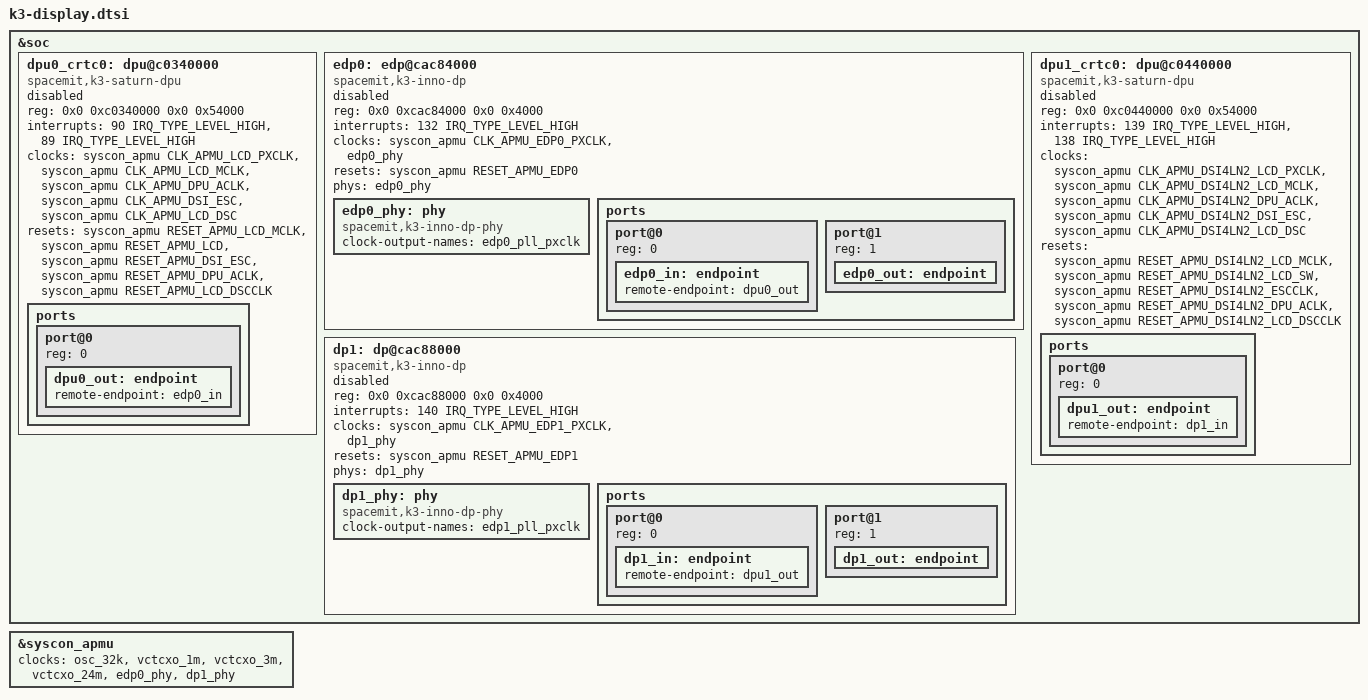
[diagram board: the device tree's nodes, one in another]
// SPDX-License-Identifier: (GPL-2.0 OR MIT)
/*
 * SpacemiT K3 display subsystem (DPU0/eDP0 + DPU1/DP1) shared
 * device-tree definitions for inclusion alongside k3.dtsi.
 *
 * Copyright (C) 2026 SpacemiT Co., Ltd.
 */

#include <dt-bindings/clock/spacemit,k3-clocks.h>
#include <dt-bindings/reset/spacemit,k3-resets.h>
#include <dt-bindings/interrupt-controller/irq.h>

&soc {
	dpu0_crtc0: dpu@c0340000 {
		compatible = "spacemit,k3-saturn-dpu";
		reg = <0x0 0xc0340000 0x0 0x54000>;
		interrupts = <90 IRQ_TYPE_LEVEL_HIGH>,
			     <89 IRQ_TYPE_LEVEL_HIGH>;
		interrupt-names = "online", "offline";
		clocks = <&syscon_apmu CLK_APMU_LCD_PXCLK>,
			 <&syscon_apmu CLK_APMU_LCD_MCLK>,
			 <&syscon_apmu CLK_APMU_DPU_ACLK>,
			 <&syscon_apmu CLK_APMU_DSI_ESC>,
			 <&syscon_apmu CLK_APMU_LCD_DSC>;
		clock-names = "pxclk", "mclk", "aclk", "escclk", "dscclk";
		resets = <&syscon_apmu RESET_APMU_LCD_MCLK>,
			 <&syscon_apmu RESET_APMU_LCD>,
			 <&syscon_apmu RESET_APMU_DSI_ESC>,
			 <&syscon_apmu RESET_APMU_DPU_ACLK>,
			 <&syscon_apmu RESET_APMU_LCD_DSCCLK>;
		reset-names = "mclk", "lcd", "esc",
			      "aclk", "dsc";
		status = "disabled";

		ports {
			#address-cells = <1>;
			#size-cells = <0>;

			port@0 {
				reg = <0>;
				dpu0_out: endpoint {
					remote-endpoint = <&edp0_in>;
				};
			};
		};
	};

	edp0: edp@cac84000 {
		compatible = "spacemit,k3-inno-dp";
		reg = <0x0 0xcac84000 0x0 0x4000>;
		interrupts = <132 IRQ_TYPE_LEVEL_HIGH>;
		clocks = <&syscon_apmu CLK_APMU_EDP0_PXCLK>, <&edp0_phy>;
		clock-names = "pxclk", "pll";
		resets = <&syscon_apmu RESET_APMU_EDP0>;
		phys = <&edp0_phy>;
		phy-names = "dp";
		status = "disabled";

		edp0_phy: phy {
			compatible = "spacemit,k3-inno-dp-phy";
			#phy-cells = <0>;
			#clock-cells = <0>;
			clock-output-names = "edp0_pll_pxclk";
		};

		ports {
			#address-cells = <1>;
			#size-cells = <0>;

			port@0 {
				reg = <0>;
				edp0_in: endpoint {
					remote-endpoint = <&dpu0_out>;
				};
			};

			port@1 {
				reg = <1>;
				edp0_out: endpoint {
				};
			};
		};
	};

	dpu1_crtc0: dpu@c0440000 {
		compatible = "spacemit,k3-saturn-dpu";
		reg = <0x0 0xc0440000 0x0 0x54000>;
		interrupts = <139 IRQ_TYPE_LEVEL_HIGH>,
			     <138 IRQ_TYPE_LEVEL_HIGH>;
		interrupt-names = "online", "offline";
		clocks = <&syscon_apmu CLK_APMU_DSI4LN2_LCD_PXCLK>,
			 <&syscon_apmu CLK_APMU_DSI4LN2_LCD_MCLK>,
			 <&syscon_apmu CLK_APMU_DSI4LN2_DPU_ACLK>,
			 <&syscon_apmu CLK_APMU_DSI4LN2_DSI_ESC>,
			 <&syscon_apmu CLK_APMU_DSI4LN2_LCD_DSC>;
		clock-names = "pxclk", "mclk", "aclk", "escclk", "dscclk";
		resets = <&syscon_apmu RESET_APMU_DSI4LN2_LCD_MCLK>,
			 <&syscon_apmu RESET_APMU_DSI4LN2_LCD_SW>,
			 <&syscon_apmu RESET_APMU_DSI4LN2_ESCCLK>,
			 <&syscon_apmu RESET_APMU_DSI4LN2_DPU_ACLK>,
			 <&syscon_apmu RESET_APMU_DSI4LN2_LCD_DSCCLK>;
		reset-names = "mclk", "lcd", "esc",
			      "aclk", "dsc";
		status = "disabled";

		ports {
			#address-cells = <1>;
			#size-cells = <0>;

			port@0 {
				reg = <0>;
				dpu1_out: endpoint {
					remote-endpoint = <&dp1_in>;
				};
			};
		};
	};

	dp1: dp@cac88000 {
		compatible = "spacemit,k3-inno-dp";
		reg = <0x0 0xcac88000 0x0 0x4000>;
		interrupts = <140 IRQ_TYPE_LEVEL_HIGH>;
		clocks = <&syscon_apmu CLK_APMU_EDP1_PXCLK>, <&dp1_phy>;
		clock-names = "pxclk", "pll";
		resets = <&syscon_apmu RESET_APMU_EDP1>;
		phys = <&dp1_phy>;
		phy-names = "dp";
		status = "disabled";

		dp1_phy: phy {
			compatible = "spacemit,k3-inno-dp-phy";
			#phy-cells = <0>;
			#clock-cells = <0>;
			clock-output-names = "edp1_pll_pxclk";
		};

		ports {
			#address-cells = <1>;
			#size-cells = <0>;

			port@0 {
				reg = <0>;
				dp1_in: endpoint {
					remote-endpoint = <&dpu1_out>;
				};
			};

			port@1 {
				reg = <1>;
				dp1_out: endpoint {
				};
			};
		};
	};
};

/*
 * Feed the PHY PLL pixel clocks back in as the APMU mux parents. This lives
 * here, not in k3.dtsi: the PHYs only exist where this file is included.
 */
&syscon_apmu {
	clocks = <&osc_32k>, <&vctcxo_1m>, <&vctcxo_3m>, <&vctcxo_24m>,
		 <&edp0_phy>, <&dp1_phy>;
	clock-names = "osc", "vctcxo_1m", "vctcxo_3m", "vctcxo_24m",
		      "edp0_pll_pxclk", "edp1_pll_pxclk";
};
